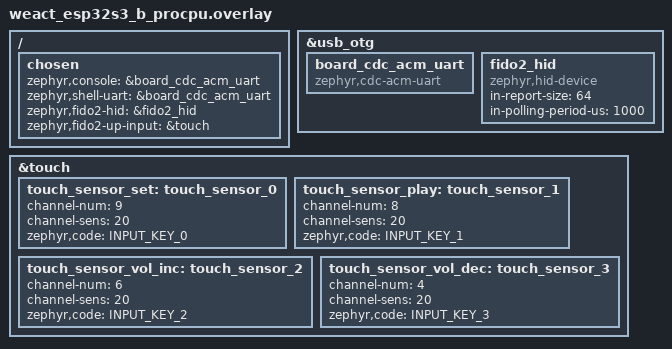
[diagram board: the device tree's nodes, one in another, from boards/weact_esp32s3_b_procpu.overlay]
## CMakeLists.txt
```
# SPDX-License-Identifier: Apache-2.0

cmake_minimum_required(VERSION 3.28.0)
find_package(Zephyr REQUIRED HINTS $ENV{ZEPHYR_BASE})
project(fido2)

if(CONFIG_FIDO2_TRANSPORT_USB_HID)
  include(${ZEPHYR_BASE}/samples/subsys/usb/common/common.cmake)
endif()

target_sources(app PRIVATE src/main.c)
```

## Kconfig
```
# Copyright (c) 2026 Siratul Islam <email@sirat.me>
# Copyright (c) 2026 Jan-Philipp Schmale <jan-philipp.schmale@teratron.de>
# SPDX-License-Identifier: Apache-2.0

mainmenu "FIDO2 Sample Application"

rsource "Kconfig.bt"

source "samples/subsys/usb/common/Kconfig.sample_usbd"

source "Kconfig.zephyr"
```

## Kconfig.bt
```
# Copyright (c) 2026 Siratul Islam <email@sirat.me>
# Copyright (c) 2026 Jan-Philipp Schmale <jan-philipp.schmale@teratron.de>
# SPDX-License-Identifier: Apache-2.0

DT_CHOSEN_Z_BT_HCI := zephyr,bt-hci

config SAMPLE_ENABLE_BT
	bool "Enable Bluetooth in the FIDO2 sample"
	default $(dt_chosen_enabled,$(DT_CHOSEN_Z_BT_HCI))
	help
	  Enable Bluetooth LE support and the FIDO2 Bluetooth LE transport
	  in the FIDO2 sample.

if SAMPLE_ENABLE_BT

configdefault BT
	default y

configdefault FIDO2_TRANSPORT_BLE
	default y

configdefault BT_PERIPHERAL
	default y

configdefault BT_SMP
	default y

configdefault BT_SETTINGS
	default y

configdefault BT_DEVICE_NAME
	default "Zephyr FIDO2"

configdefault BT_BONDING_REQUIRED
	default y

configdefault BT_USER_CONN_PARAM_REJECTED
	default y

configdefault BT_DIS
	default y

configdefault BT_DIS_FW_REV
	default y

configdefault BT_DIS_MANUF_NAME_STR
	default "Zephyr Project"

configdefault BT_DIS_MODEL_NUMBER_STR
	default "FIDO2 Bluetooth LE Sample"

configdefault BT_DIS_FW_REV_STR
	default "0.1"

configdefault BT_RX_STACK_SIZE
	default 2048

configdefault FIDO2_BLE_RX_WORKQ_STACK_SIZE
	default 1024

configdefault BT_PERIPHERAL_PREF_MIN_INT
	default 24

configdefault BT_PERIPHERAL_PREF_MAX_INT
	default 40

configdefault BT_PERIPHERAL_PREF_LATENCY
	default 0

configdefault BT_PERIPHERAL_PREF_TIMEOUT
	default 400

endif # SAMPLE_ENABLE_BT
```

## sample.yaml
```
sample:
  name: FIDO2 Authenticator
common:
  depends_on:
    - usbd
  harness: console
  harness_config:
    type: one_line
    regex:
      - "FIDO2 authenticator ready"
  integration_platforms:
    - weact_stm32wb55_core
tests:
  sample.authentication.fido2: {}
```

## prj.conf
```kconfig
CONFIG_USB_DEVICE_STACK_NEXT=y
CONFIG_USBD_HID_SUPPORT=y
CONFIG_SAMPLE_USBD_PID=0x0012

CONFIG_FIDO2=y
CONFIG_FIDO2_TRANSPORT_USB_HID=y
CONFIG_FIDO2_LOG_LEVEL_INF=y

# zephyrFido2SAMPL
CONFIG_FIDO2_AAGUID="7a65706879724669646f3253414d504c"

CONFIG_FLASH=y
CONFIG_FLASH_MAP=y
CONFIG_NVS=y
CONFIG_SETTINGS=y
CONFIG_SETTINGS_NVS=y

CONFIG_LOG=y
CONFIG_GPIO=y
CONFIG_INPUT=y

CONFIG_MAIN_STACK_SIZE=4096
```

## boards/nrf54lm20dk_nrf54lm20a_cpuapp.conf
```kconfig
# Work around RRAM write timeouts with Bluetooth LE radio synchronization.
CONFIG_SOC_FLASH_NRF_RADIO_SYNC_NONE=y
```

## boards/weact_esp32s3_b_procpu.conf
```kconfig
CONFIG_USBD_CDC_ACM_CLASS=y
CONFIG_CDC_ACM_SERIAL_INITIALIZE_AT_BOOT=n
CONFIG_USBD_CDC_ACM_LOG_LEVEL_OFF=y
CONFIG_SOC_FAMILY_ESPRESSIF_SPIRAM=y
CONFIG_SOC_FAMILY_ESPRESSIF_SPIRAM_MODE_OCT=y
CONFIG_INPUT_ESP32_TOUCH_SENSOR=y
```

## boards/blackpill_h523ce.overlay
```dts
/*
 * Copyright (c) 2026 Siratul Islam <email@sirat.me>
 *
 * SPDX-License-Identifier: Apache-2.0
 */

/ {
	buttons: gpio_keys {};

	chosen {
		zephyr,fido2-hid = &fido2_hid;
		zephyr,fido2-up-input = &buttons;
	};
};

&zephyr_udc0 {
	status = "okay";

	fido2_hid: fido2_hid {
		compatible = "zephyr,hid-device";
		in-report-size = <64>;
		in-polling-period-us = <1000>;
	};
};

&flash0 {
	partitions {
		#address-cells = <1>;
		#size-cells = <1>;
		ranges;

		storage_partition: partition@68000 {
			compatible = "zephyr,mapped-partition";
			label = "storage";
			reg = <0x00068000 DT_SIZE_K(96)>;
		};
	};
};
```

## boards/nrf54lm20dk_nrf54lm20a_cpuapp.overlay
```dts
/*
 * Copyright (c) 2026 Jan Philipp Schmale <jan-philipp.schmale@teratron.de>
 *
 * SPDX-License-Identifier: Apache-2.0
 */

/ {
	chosen {
		zephyr,fido2-hid = &fido2_hid;
		zephyr,fido2-up-input = &{/buttons};
	};
};

&zephyr_udc0 {
	status = "okay";

	fido2_hid: fido2_hid {
		compatible = "zephyr,hid-device";
		in-report-size = <64>;
		in-polling-period-us = <1000>;
	};
};
```

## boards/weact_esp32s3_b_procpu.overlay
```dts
/*
 * Copyright (c) 2026 Siratul Islam <email@sirat.me>
 *
 * SPDX-License-Identifier: Apache-2.0
 */

#include <zephyr/dt-bindings/input/input-event-codes.h>
#include <zephyr/dt-bindings/input/esp32-touch-sensor-input.h>

/ {
	chosen {
		zephyr,console = &board_cdc_acm_uart;
		zephyr,shell-uart = &board_cdc_acm_uart;
		zephyr,fido2-hid = &fido2_hid;
		zephyr,fido2-up-input = &touch;
	};
};

zephyr_udc0: &usb_otg {
	status = "okay";

	board_cdc_acm_uart: board_cdc_acm_uart {
		compatible = "zephyr,cdc-acm-uart";
	};

	fido2_hid: fido2_hid {
		compatible = "zephyr,hid-device";
		in-report-size = <64>;
		in-polling-period-us = <1000>;
	};
};

&touch {
	status = "okay";

	touch_sensor_set: touch_sensor_0 {
		channel-num = <9>;
		channel-sens = <20>;
		zephyr,code = <INPUT_KEY_0>;
	};

	touch_sensor_play: touch_sensor_1 {
		channel-num = <8>;
		channel-sens = <20>;
		zephyr,code = <INPUT_KEY_1>;
	};

	touch_sensor_vol_inc: touch_sensor_2 {
		channel-num = <6>;
		channel-sens = <20>;
		zephyr,code = <INPUT_KEY_2>;
	};

	touch_sensor_vol_dec: touch_sensor_3 {
		channel-num = <4>;
		channel-sens = <20>;
		zephyr,code = <INPUT_KEY_3>;
	};
};
```

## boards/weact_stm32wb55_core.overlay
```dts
/*
 * Copyright (c) 2026 Siratul Islam <email@sirat.me>
 *
 * SPDX-License-Identifier: Apache-2.0
 */

/ {
	buttons: gpio_keys {};

	chosen {
		zephyr,fido2-hid = &fido2_hid;
		zephyr,fido2-up-input = &buttons;
	};
};

&zephyr_udc0 {
	status = "okay";

	fido2_hid: fido2_hid {
		compatible = "zephyr,hid-device";
		in-report-size = <64>;
		in-polling-period-us = <1000>;
	};
};
```

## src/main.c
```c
/*
 * Copyright (c) 2026 Siratul Islam <email@sirat.me>
 *
 * SPDX-License-Identifier: Apache-2.0
 */

#include <zephyr/kernel.h>
#include <zephyr/logging/log.h>
#include <zephyr/authentication/fido2/fido2.h>
#include <zephyr/authentication/fido2/fido2_transport.h>
#include <zephyr/bluetooth/uuid.h>
#include <zephyr/bluetooth/bluetooth.h>
#include <zephyr/settings/settings.h>
#include <zephyr/bluetooth/conn.h>

#if DT_NODE_HAS_STATUS(DT_ALIAS(led0), okay)
#include <zephyr/drivers/gpio.h>
#define HAS_STATUS_LED 1
#endif

#ifdef CONFIG_FIDO2_TRANSPORT_USB_HID
#include <sample_usbd.h>
#include <zephyr/usb/usbd.h>
#include <zephyr/usb/class/usbd_hid.h>
#endif

LOG_MODULE_REGISTER(main, LOG_LEVEL_INF);

#ifdef HAS_STATUS_LED
#define BLINK_INTERVAL_MS 150

static const struct gpio_dt_spec status_led = GPIO_DT_SPEC_GET(DT_ALIAS(led0), gpios);

static void blink_expiry(struct k_timer *timer)
{
	ARG_UNUSED(timer);
	gpio_pin_toggle_dt(&status_led);
}

K_TIMER_DEFINE(blink_timer, blink_expiry, NULL);
#endif

#ifdef CONFIG_FIDO2_TRANSPORT_BLE
/*
 * The FIDO service UUID must be present in the advertising data. This sample
 * always advertises in pairing mode, so the General Discoverable flag is set.
 */
static const struct bt_data ad[] = {
	BT_DATA_BYTES(BT_DATA_FLAGS, (BT_LE_AD_GENERAL | BT_LE_AD_NO_BREDR)),
	BT_DATA_BYTES(BT_DATA_UUID16_ALL, BT_UUID_16_ENCODE(FIDO2_BLE_SERVICE_UUID_VAL)),
};

/*
 * FIDO service data in the scan response makes pairing mode discoverable to
 * clients that do not expose the GAP discoverable flags to applications.
 */
static const uint8_t fido_service_data[] = {
	BT_UUID_16_ENCODE(FIDO2_BLE_SERVICE_UUID_VAL),
	FIDO2_BLE_SERVICE_DATA_PAIRING_MODE,
};

static const struct bt_data sd[] = {
	BT_DATA(BT_DATA_SVC_DATA16, fido_service_data, sizeof(fido_service_data)),
	BT_DATA(BT_DATA_NAME_COMPLETE, CONFIG_BT_DEVICE_NAME, sizeof(CONFIG_BT_DEVICE_NAME) - 1U),
};

static int start_advertising(void)
{
	int err;

	err = bt_le_adv_start(BT_LE_ADV_CONN_FAST_1, ad, ARRAY_SIZE(ad), sd, ARRAY_SIZE(sd));
	if (err != 0) {
		LOG_ERR("Failed to start FIDO2 Bluetooth LE advertising: %d", err);
		return err;
	}

	LOG_INF("FIDO2 Bluetooth LE advertising started");
	return 0;
}

static void connection_recycled(void)
{
	(void)start_advertising();
}

BT_CONN_CB_DEFINE(sample_conn_callbacks) = {
	.recycled = connection_recycled,
};
#endif /* CONFIG_FIDO2_TRANSPORT_BLE */

#ifdef CONFIG_FIDO2_TRANSPORT_USB_HID
struct usbd_context *sample_usbd;

static void msg_cb(struct usbd_context *const usbd_ctx, const struct usbd_msg *const msg)
{
	LOG_INF("USBD message: %s", usbd_msg_type_string(msg->type));

	if (msg->type == USBD_MSG_CONFIGURATION) {
		LOG_INF("\tConfiguration value %d", msg->status);
	}

	if (usbd_can_detect_vbus(usbd_ctx)) {
		if (msg->type == USBD_MSG_VBUS_READY) {
			if (usbd_enable(usbd_ctx)) {
				LOG_ERR("Failed to enable device support");
			}
		}

		if (msg->type == USBD_MSG_VBUS_REMOVED) {
			if (usbd_disable(usbd_ctx)) {
				LOG_ERR("Failed to disable device support");
			}
		}
	}
}
#endif /* CONFIG_FIDO2_TRANSPORT_USB_HID */

static const char *fido2_state_to_str(enum fido2_runtime_state state)
{
	switch (state) {
	case FIDO2_RUNTIME_STATE_STOPPED:
		return "stopped";
	case FIDO2_RUNTIME_STATE_IDLE:
		return "idle";
	case FIDO2_RUNTIME_STATE_WAITING_USER_PRESENCE:
		return "waiting_user_presence";
	case FIDO2_RUNTIME_STATE_PROCESSING:
		return "processing";
	default:
		return "unknown";
	}
}

static void fido2_state_changed(enum fido2_runtime_state state, void *user_data)
{
	ARG_UNUSED(user_data);

	LOG_INF("FIDO2 runtime state: %s", fido2_state_to_str(state));

#ifdef HAS_STATUS_LED
	switch (state) {
	case FIDO2_RUNTIME_STATE_WAITING_USER_PRESENCE:
		k_timer_start(&blink_timer, K_NO_WAIT, K_MSEC(BLINK_INTERVAL_MS));
		break;
	case FIDO2_RUNTIME_STATE_PROCESSING:
		k_timer_stop(&blink_timer);
		gpio_pin_set_dt(&status_led, 1);
		break;
	default:
		k_timer_stop(&blink_timer);
		gpio_pin_set_dt(&status_led, 0);
		break;
	}
#endif
}

int main(void)
{
	int ret;

	ret = fido2_init();
	if (ret) {
		LOG_ERR("FIDO2 init failed: %d", ret);
		return ret;
	}

#ifdef HAS_STATUS_LED
	if (!gpio_is_ready_dt(&status_led)) {
		LOG_WRN("led0 not ready, LED indication disabled");
	} else {
		ret = gpio_pin_configure_dt(&status_led, GPIO_OUTPUT_INACTIVE);
		if (ret) {
			LOG_WRN("Failed to configure led0: %d", ret);
		}
	}
#endif /* HAS_STATUS_LED */

	ret = fido2_set_state_callback(fido2_state_changed, NULL);
	if (ret) {
		LOG_ERR("Failed to register state callback: %d", ret);
		return ret;
	}

#ifdef CONFIG_FIDO2_TRANSPORT_USB_HID
	sample_usbd = sample_usbd_init_device(msg_cb);
	if (sample_usbd == NULL) {
		LOG_ERR("Failed to initialize USB device");
		return -ENODEV;
	}

	if (!usbd_can_detect_vbus(sample_usbd)) {
		ret = usbd_enable(sample_usbd);
		if (ret) {
			LOG_ERR("Failed to enable device support");
			return ret;
		}
	}
#endif /* CONFIG_FIDO2_TRANSPORT_USB_HID */

	ret = fido2_start();
	if (ret != 0) {
		LOG_ERR("FIDO2 start failed: %d", ret);
		return ret;
	}

	LOG_INF("FIDO2 started");

#ifdef CONFIG_FIDO2_TRANSPORT_BLE
	ret = bt_enable(NULL);
	if (ret != 0) {
		LOG_ERR("Bluetooth init failed: %d", ret);
		return ret;
	}

	if (IS_ENABLED(CONFIG_BT_SETTINGS)) {
		ret = settings_load();
		if (ret != 0) {
			LOG_ERR("Failed to load Bluetooth settings: %d", ret);
			return ret;
		}
	}

	ret = start_advertising();
	if (ret != 0) {
		return ret;
	}
#endif /* CONFIG_FIDO2_TRANSPORT_BLE */

	LOG_INF("FIDO2 authenticator ready");
	k_sleep(K_FOREVER);

	return 0;
}
```
